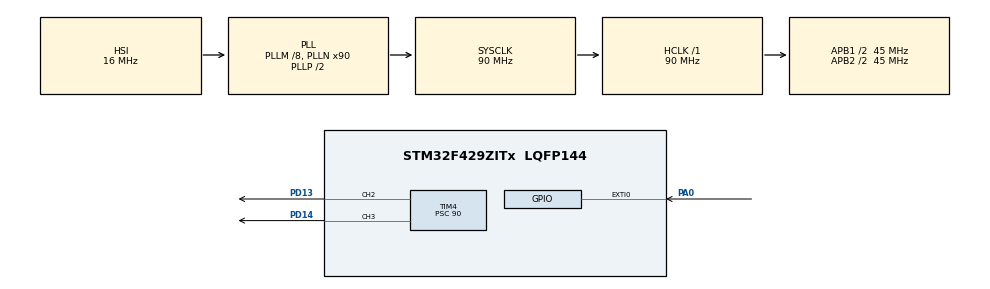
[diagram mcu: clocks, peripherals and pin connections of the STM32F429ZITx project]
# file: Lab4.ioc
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Mcu.Family=STM32F4
Mcu.Name=STM32F429ZITx
Mcu.Package=LQFP144
NVIC.EXTI0_IRQn=true\:0\:0\:false\:false\:true\:true\:true\:true
NVIC.PriorityGroup=NVIC_PRIORITYGROUP_4
PA0/WKUP.GPIO_ModeDefaultEXTI=GPIO_MODE_IT_RISING
PA0/WKUP.Signal=GPXTI0
PA13.Mode=Serial_Wire
PA13.Signal=SYS_JTMS-SWDIO
PA14.Mode=Serial_Wire
PA14.Signal=SYS_JTCK-SWCLK
PD13.Signal=S_TIM4_CH2
PD14.Signal=S_TIM4_CH3
PH0/OSC_IN.Mode=HSE-External-Oscillator
PH0/OSC_IN.Signal=RCC_OSC_IN
PH1/OSC_OUT.Mode=HSE-External-Oscillator
PH1/OSC_OUT.Signal=RCC_OSC_OUT
ProjectManager.HeapSize=0x200
ProjectManager.StackSize=0x400
ProjectManager.TargetToolchain=STM32CubeIDE
RCC.48MHZClocksFreq_Value=45000000
RCC.AHBFreq_Value=90000000
RCC.APB1CLKDivider=RCC_HCLK_DIV2
RCC.APB1Freq_Value=45000000
RCC.APB1TimFreq_Value=90000000
RCC.APB2CLKDivider=RCC_HCLK_DIV2
RCC.APB2Freq_Value=45000000
RCC.APB2TimFreq_Value=90000000
RCC.CortexFreq_Value=90000000
RCC.HCLKFreq_Value=90000000
RCC.HSE_VALUE=8000000
RCC.HSI_VALUE=16000000
RCC.LSE_VALUE=32768
RCC.PLLM=8
RCC.PLLN=90
RCC.SYSCLKFreq_VALUE=90000000
RCC.SYSCLKSource=RCC_SYSCLKSOURCE_PLLCLK
RCC.VCOOutputFreq_Value=180000000
SH.S_TIM4_CH2.0=TIM4_CH2,PWM Generation2 CH2
SH.S_TIM4_CH3.0=TIM4_CH3,PWM Generation3 CH3
TIM4.Channel-PWM\ Generation2\ CH2=TIM_CHANNEL_2
TIM4.Channel-PWM\ Generation3\ CH3=TIM_CHANNEL_3
TIM4.Period=99
TIM4.Prescaler=90
VP_TIM4_VS_ClockSourceINT.Mode=Internal
board=custom

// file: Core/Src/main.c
/* USER CODE BEGIN Header */
/**
  ******************************************************************************
  * @file           : main.c
  * @brief          : Main program body
  ******************************************************************************
  * @attention
  *
  * Copyright (c) 2024 STMicroelectronics.
  * All rights reserved.
  *
  * This software is licensed under terms that can be found in the LICENSE file
  * in the root directory of this software component.
  * If no LICENSE file comes with this software, it is provided AS-IS.
  *
  ******************************************************************************
  */
/* USER CODE END Header */
#include "main.h"

 TIM_HandleTypeDef htim4;

void SystemClock_Config(void);
static void MX_GPIO_Init(void);
static void MX_TIM4_Init(void);

/* USER CODE BEGIN 0 */
int intensity = 0;
int flag = 0;
int miliseconds = 0;

double overflowPeriod() {
  uint32_t ctrl_reg = SysTick->CTRL;
  uint32_t prescaler = (ctrl_reg >> 2) & 0x1;
  double timerFreq;
  double t;
  double overflowPeriod;

  if (prescaler == 0) {
    timerFreq = SystemCoreClock / 8;
    t = 1 / timerFreq;
    overflowPeriod = (double)(t * (SysTick->LOAD + 1));

  } else {
    timerFreq = SystemCoreClock;
    t = 1 / timerFreq;
    overflowPeriod = (double)(t * (SysTick->LOAD + 1));
  }

  return overflowPeriod;
}
/* USER CODE END 0 */

int main(void)
{

  /* MCU Configuration--------------------------------------------------------*/

  /* Reset of all peripherals, Initializes the Flash interface and the Systick. */
  HAL_Init();

  /* Configure the system clock */
  SystemClock_Config();

  /* Initialize all configured peripherals */
  MX_GPIO_Init();
  MX_TIM4_Init();
  /* USER CODE BEGIN 2 */
  double a = overflowPeriod();

  RCC->APB1ENR |= RCC_APB1ENR_TIM4EN;
  RCC->AHB1ENR |= RCC_AHB1ENR_GPIOGEN | RCC_AHB1ENR_GPIODEN | RCC_AHB1ENR_GPIOAEN;
  RCC->APB2ENR |= RCC_APB2ENR_SYSCFGEN;

  TIM4->PSC = 8999;
  TIM4->ARR = 99;

  TIM4->CCER |= (TIM_CCER_CC2E | TIM_CCER_CC3E);

  GPIOG->MODER &= ~GPIO_MODER_MODE13_0;
  GPIOG->MODER &= ~GPIO_MODER_MODE13_1;

  GPIOG->MODER &= ~GPIO_MODER_MODE14_0;
  GPIOG->MODER &= ~GPIO_MODER_MODE14_1;

  GPIOD->MODER |= GPIO_MODER_MODE14_1;
  GPIOD->MODER &= ~GPIO_MODER_MODE13_0;

  GPIOD->MODER |= GPIO_MODER_MODE14_1;
  GPIOD->MODER &= ~GPIO_MODER_MODE13_0;

  GPIOA->MODER &= ~GPIO_MODER_MODE0_1;
  GPIOA->MODER &= ~GPIO_MODER_MODE0_0;

  TIM4->CR1 |= TIM_CR1_CEN;

  SYSCFG->EXTICR[0] &= ~SYSCFG_EXTICR1_EXTI0;

  EXTI->RTSR |= EXTI_RTSR_TR0;
  EXTI->IMR |= EXTI_IMR_MR0;

  /* USER CODE END 2 */

  /* Infinite loop */
  /* USER CODE BEGIN WHILE */

  while (1)
  {
		  TIM4->CCR2 = intensity;
		  TIM4->CCR3 = intensity;
  }
    /* USER CODE END WHILE */

}

void SystemClock_Config(void)
{
  RCC_OscInitTypeDef RCC_OscInitStruct = {0};
  RCC_ClkInitTypeDef RCC_ClkInitStruct = {0};

  /** Configure the main internal regulator output voltage
  */
  __HAL_RCC_PWR_CLK_ENABLE();
  __HAL_PWR_VOLTAGESCALING_CONFIG(PWR_REGULATOR_VOLTAGE_SCALE3);

  /** Initializes the RCC Oscillators according to the specified parameters
  * in the RCC_OscInitTypeDef structure.
  */
  RCC_OscInitStruct.OscillatorType = RCC_OSCILLATORTYPE_HSI;
  RCC_OscInitStruct.HSIState = RCC_HSI_ON;
  RCC_OscInitStruct.HSICalibrationValue = RCC_HSICALIBRATION_DEFAULT;
  RCC_OscInitStruct.PLL.PLLState = RCC_PLL_ON;
  RCC_OscInitStruct.PLL.PLLSource = RCC_PLLSOURCE_HSI;
  RCC_OscInitStruct.PLL.PLLM = 8;
  RCC_OscInitStruct.PLL.PLLN = 90;
  RCC_OscInitStruct.PLL.PLLP = RCC_PLLP_DIV2;
  RCC_OscInitStruct.PLL.PLLQ = 4;
  if (HAL_RCC_OscConfig(&RCC_OscInitStruct) != HAL_OK)
  {
    Error_Handler();
  }

  /** Activate the Over-Drive mode
  */
  if (HAL_PWREx_EnableOverDrive() != HAL_OK)
  {
    Error_Handler();
  }

  /** Initializes the CPU, AHB and APB buses clocks
  */
  RCC_ClkInitStruct.ClockType = RCC_CLOCKTYPE_HCLK|RCC_CLOCKTYPE_SYSCLK
                              |RCC_CLOCKTYPE_PCLK1|RCC_CLOCKTYPE_PCLK2;
  RCC_ClkInitStruct.SYSCLKSource = RCC_SYSCLKSOURCE_PLLCLK;
  RCC_ClkInitStruct.AHBCLKDivider = RCC_SYSCLK_DIV1;
  RCC_ClkInitStruct.APB1CLKDivider = RCC_HCLK_DIV2;
  RCC_ClkInitStruct.APB2CLKDivider = RCC_HCLK_DIV2;

  if (HAL_RCC_ClockConfig(&RCC_ClkInitStruct, FLASH_LATENCY_2) != HAL_OK)
  {
    Error_Handler();
  }
}

static void MX_TIM4_Init(void)
{

  TIM_ClockConfigTypeDef sClockSourceConfig = {0};
  TIM_MasterConfigTypeDef sMasterConfig = {0};
  TIM_OC_InitTypeDef sConfigOC = {0};

  htim4.Instance = TIM4;
  htim4.Init.Prescaler = 90;
  htim4.Init.CounterMode = TIM_COUNTERMODE_UP;
  htim4.Init.Period = 99;
  htim4.Init.ClockDivision = TIM_CLOCKDIVISION_DIV1;
  htim4.Init.AutoReloadPreload = TIM_AUTORELOAD_PRELOAD_DISABLE;
  if (HAL_TIM_Base_Init(&htim4) != HAL_OK)
  {
    Error_Handler();
  }
  sClockSourceConfig.ClockSource = TIM_CLOCKSOURCE_INTERNAL;
  if (HAL_TIM_ConfigClockSource(&htim4, &sClockSourceConfig) != HAL_OK)
  {
    Error_Handler();
  }
  if (HAL_TIM_PWM_Init(&htim4) != HAL_OK)
  {
    Error_Handler();
  }
  sMasterConfig.MasterOutputTrigger = TIM_TRGO_RESET;
  sMasterConfig.MasterSlaveMode = TIM_MASTERSLAVEMODE_DISABLE;
  if (HAL_TIMEx_MasterConfigSynchronization(&htim4, &sMasterConfig) != HAL_OK)
  {
    Error_Handler();
  }
  sConfigOC.OCMode = TIM_OCMODE_PWM1;
  sConfigOC.Pulse = 0;
  sConfigOC.OCPolarity = TIM_OCPOLARITY_HIGH;
  sConfigOC.OCFastMode = TIM_OCFAST_DISABLE;
  if (HAL_TIM_PWM_ConfigChannel(&htim4, &sConfigOC, TIM_CHANNEL_2) != HAL_OK)
  {
    Error_Handler();
  }
  if (HAL_TIM_PWM_ConfigChannel(&htim4, &sConfigOC, TIM_CHANNEL_3) != HAL_OK)
  {
    Error_Handler();
  }
  HAL_TIM_MspPostInit(&htim4);

}

static void MX_GPIO_Init(void)
{
  GPIO_InitTypeDef GPIO_InitStruct = {0};

  /* GPIO Ports Clock Enable */
  __HAL_RCC_GPIOH_CLK_ENABLE();
  __HAL_RCC_GPIOA_CLK_ENABLE();
  __HAL_RCC_GPIOD_CLK_ENABLE();

  /*Configure GPIO pin : PA0 */
  GPIO_InitStruct.Pin = GPIO_PIN_0;
  GPIO_InitStruct.Mode = GPIO_MODE_IT_RISING;
  GPIO_InitStruct.Pull = GPIO_NOPULL;
  HAL_GPIO_Init(GPIOA, &GPIO_InitStruct);

  /* EXTI interrupt init*/
  HAL_NVIC_SetPriority(EXTI0_IRQn, 0, 0);
  HAL_NVIC_EnableIRQ(EXTI0_IRQn);

}

void Error_Handler(void)
{
  __disable_irq();
  while (1)
  {
  }
}
